# VPAC0_CTSET2_WRAP_CFG_CTSET2_CFG register map
Vendor: Texas Instruments
Peripheral module from a debugger description file (folder J7ES).
Registers are 32-bit, access per field, reset 0x0 unless marked. A register's access mark holds for its fields unless they carry their own. Offsets are as the file gives them; lines under a group give offsets from that group; [hi:lo] are bit positions; {n}, {i} and the like mark numbered series; 'fields as' and 'values as' point back to an identical list; <NAME> marks a mode.

## VPAC0_CTSET2_WRAP_CFG_CTSET2_CFG
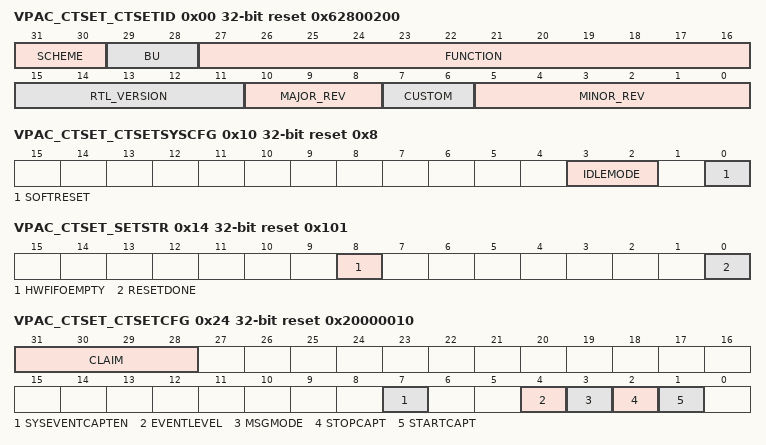
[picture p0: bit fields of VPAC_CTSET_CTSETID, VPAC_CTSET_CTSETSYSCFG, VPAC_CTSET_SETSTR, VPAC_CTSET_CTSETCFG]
0x00 VPAC_CTSET_CTSETID ro reset 0x62800200 — CTSET identification register
  [31:30] SCHEME — Used to distinguish between old Scheme and current
  [29:28] BU — The value 10b designates this as Processor Business Unit IP
  [27:16] FUNCTION — Function : Indicates a Debug IP (0x2nn) and 0x80 is the identifier for CT-SET
  [15:11] RTL_VERSION — This field changes on bug fix, and resets to '0' when either Minor Revision or Major Revision field changes
  [10:8] MAJOR_REV — Major Revision.
  [7:6] CUSTOM — Indicates a special version for a particular device.
  [5:0] MINOR_REV — Minor Revision.
0x10 VPAC_CTSET_CTSETSYSCFG reset 0x8 — CTSET system configuration register
  [3:2] IDLEMODE rw — Sets the Idle Mode for CTSET (
  [0] SOFTRESET rw — This will reset entire CTSET, except the registers and the CFG interface.
0x14 VPAC_CTSET_SETSTR ro reset 0x101 — CTSET status register
  [8] HWFIFOEMPTY — System Event Trace FIFO status, 1 is empty, 0 means captured data not yet exported
  [0] RESETDONE — Reset status, 0 means reset ongoing, 1 indicates completed
0x18 VPAC_CTSET_DBGTIMELOW ro — The 32 low order bits of the debug time value supplied on the time input interface
  [31:0] DBGTIME — debug time
0x1C VPAC_CTSET_DBGTIMEHI ro — The 32 high order bits of the debug time value supplied on the time input interface
  [31:0] DBGTIME — debug time
0x24 VPAC_CTSET_CTSETCFG reset 0x20000010 — The 32 low order bits of the debug time value supplied on the time input interface The 32 high order bits of the debug time value supplied on the time input interface. Reading latches the lower 32 bits of debug time value CTSET configuration register
  [31:28] CLAIM rw — Claim control and status.
  [7] SYSEVENTCAPTEN rw — When 1 the System event capture is enabled
  [4] EVENTLEVEL rw — 0 enables low level event detection, 1 enables high level event detection
  [3] MSGMODE rw — Message generated based on event detection, 0 is sampling window, 1 is event detection
  [2] STOPCAPT rw — Stop capturing system events from external trigger detection
  [1] STARTCAPT rw — Start capturing system events from external trigger detection
0x28 VPAC_CTSET_SETSPLREG — System Event Sampling Window register
  [7:0] WINDOWSIZE rw — System events sampling window size expressed as CTSET cycles
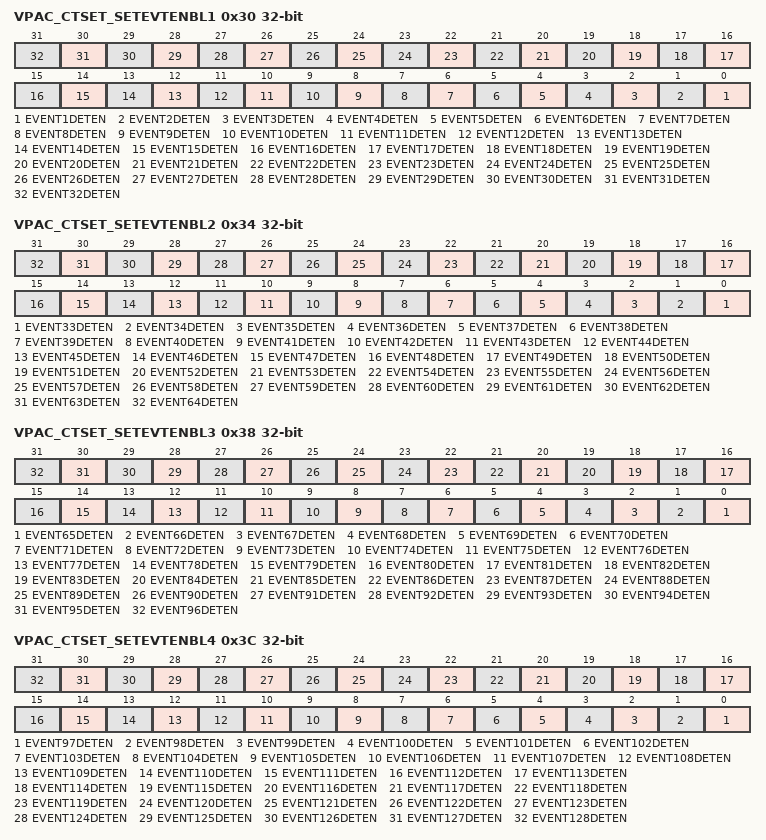
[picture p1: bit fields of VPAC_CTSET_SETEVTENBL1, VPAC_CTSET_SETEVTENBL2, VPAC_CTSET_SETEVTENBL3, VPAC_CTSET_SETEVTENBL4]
0x30 VPAC_CTSET_SETEVTENBL1 rw — System event detection enable register 1
  [n-1] EVENT{n}DETEN (n=1..32) — Event({n}) Detection Enable
0x34 VPAC_CTSET_SETEVTENBL2 rw — System event detection enable register 2 (if number of events > 32)
  [n-33] EVENT{n}DETEN (n=33..64) — Event({n}) Detection Enable
0x38 VPAC_CTSET_SETEVTENBL3 rw — System event detection enable register 3 (if number of events > 64)
  [n-65] EVENT{n}DETEN (n=65..96) — Event({n}) Detection Enable
0x3C VPAC_CTSET_SETEVTENBL4 rw — System event detection enable register 4 (if number of events > 96)
  [n-97] EVENT{n}DETEN (n=97..128) — Event({n}) Detection Enable
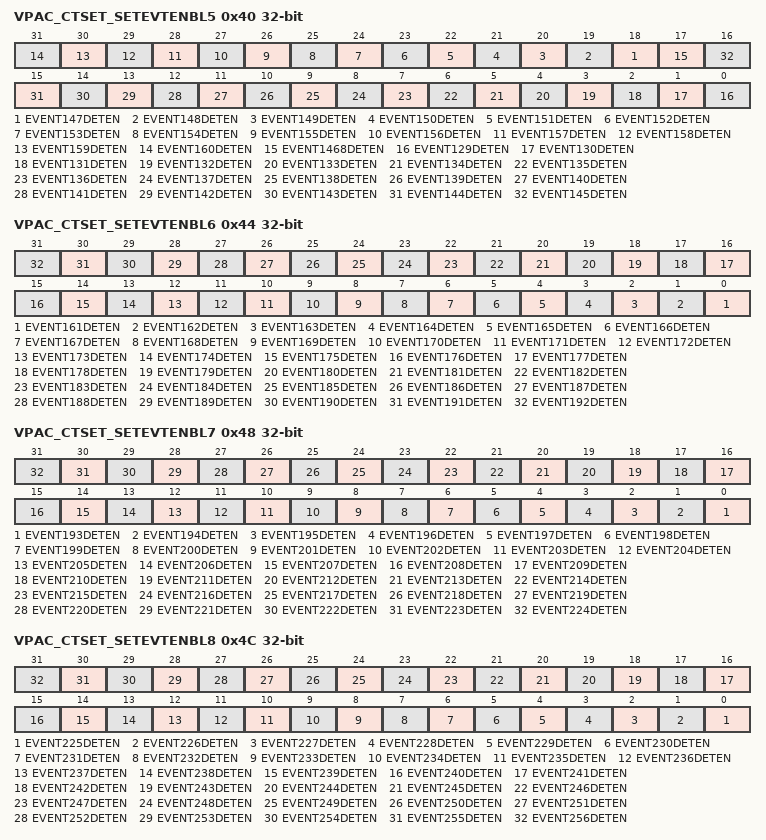
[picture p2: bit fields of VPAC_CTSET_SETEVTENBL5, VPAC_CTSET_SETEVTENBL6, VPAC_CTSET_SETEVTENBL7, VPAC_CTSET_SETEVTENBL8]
0x40 VPAC_CTSET_SETEVTENBL5 rw — System event detection enable register 5 (if number of events > 128)
  [n-129] EVENT{n}DETEN (n=147..160) — Event({n}) Detection Enable
  [17] EVENT1468DETEN — Event(146) Detection Enable
  [n-129] EVENT{n}DETEN (n=129..145) — Event({n}) Detection Enable
0x44 VPAC_CTSET_SETEVTENBL6 rw — System event detection enable register 6 (if number of events > 160)
  [n-161] EVENT{n}DETEN (n=161..192) — Event({n}) Detection Enable
0x48 VPAC_CTSET_SETEVTENBL7 rw — System event detection enable register 7 (if number of events > 192)
  [n-193] EVENT{n}DETEN (n=193..224) — Event({n}) Detection Enable
0x4C VPAC_CTSET_SETEVTENBL8 rw — System event detection enable register 8 (if number of events > 224)
  [n-225] EVENT{n}DETEN (n=225..256) — Event({n}) Detection Enable
0x50 VPAC_CTSET_SETMSTID — System Event Master ID
  [7:0] MASTID rw — HW Master ID for System Event module.
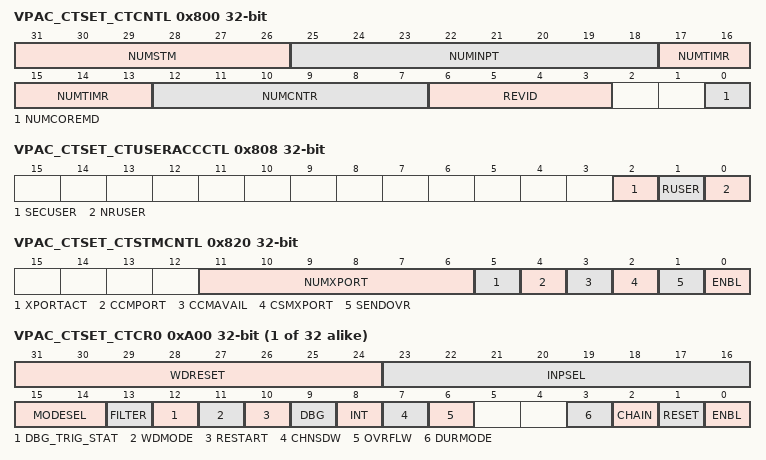
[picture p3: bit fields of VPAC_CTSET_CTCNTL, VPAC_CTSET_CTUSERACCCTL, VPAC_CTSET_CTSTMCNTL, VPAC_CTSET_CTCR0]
0x800 VPAC_CTSET_CTCNTL ro — Counter Timer Control
  [31:26] NUMSTM — Number of counters that can export via STM
  [25:18] NUMINPT — Number of event input signals
  [17:13] NUMTIMR — Number of timers in the module
  [12:7] NUMCNTR — Number of counters in the module
  [6:3] REVID — Revision ID of CTSET
  [0] NUMCOREMD — Indicated the number of mode bus interfaces, 0 is 2 CPU buses, 1 is 4 buses
0x804 VPAC_CTSET_CTNUMDBG ro — Counter Timer Number Debug Event Register
  [2:0] NUMEVT — Number of input selectors for debug events
0x808 VPAC_CTSET_CTUSERACCCTL — Counter Timer User Access Control, can only be written in priviledged mode
  [2] SECUSER rw — Counter functions while system is in Secure-User mode
  [1] RUSER rw — Counter functions while system is in Root-User mode
  [0] NRUSER rw — Counter functions while system is in in Non-Root-User mode
0x820 VPAC_CTSET_CTSTMCNTL — Counter Timer STM Control register
  [11:6] NUMXPORT ro — The total number of counters designated for export
  [5] XPORTACT ro — Indicates if a frame is currently being written to the STM.
  [4] CCMPORT rw — SW control of CCM message export
  [3] CCMAVAIL rw — CTSET supports CCM export
  [2] CSMXPORT rw — SW control of CSM message export
  [1] SENDOVR rw — Send overflow data in CSM frame
  [0] ENBL rw — CTSET STM global enable for counter/timer messages
0x824 VPAC_CTSET_CTSTMMSTID — Counter Timer STM Master ID register
  [7:0] MASTID rw — HW Master ID for System Event module
0x828 VPAC_CTSET_CTSTMINTVL — Counter Timer STM Interval Register
  [14:0] INTERVAL rw — Counter Timer Periodic export interval
0x82C VPAC_CTSET_CTSTMSEL0 rw — Counter Timer STM Counter Select Register 0. This Selects Counter 0 to 31
  [31:0] COUNTSEL — The individual bit is this field indicate whether the corresponding counter value is included in the CSM message generated via the STM interface
0x830 VPAC_CTSET_CTSTMSEL1 rw — Counter Timer STM Counter Select Register 1. This Selects Counter 32 to 63
  fields as VPAC_CTSET_CTSTMSEL0
{0x840+4i} VPAC_CTSET_CTINTVLR{i} rw (i=0..15) — These registers contain the interval match value for the corresponding timers in the CTSET. TINTVLRn are available based on number of timers instantiated.
  [31:0] INTERVAL — Interval match value for the timers in the CTSET
0x8A0 VPAC_CTSET_CTDBGSGL0 — Timer Interval Register 0. Interval match value for timer 0 in CTSET Timer Interval Register 1. Interval match value for timer 1 in CTSET Timer Interval Register 2. Interval match value for timer 2 in CTSET Timer Interval Register 3. Interval match value for timer 3 in CTSET Timer Interval Register 4. Interval match value for timer 4 in CTSET Timer Interval Register 5. Interval match value for timer 5 in CTSET Timer Interval Register 6. Interval match value for timer 6 in CTSET Timer Interval Register 7. Interval match value for timer 7 in CTSET Timer Interval Register 8. Interval match value for timer 8 in CTSET Timer Interval Register 9. Interval match value for timer 9 in CTSET Timer Interval Register 10. Interval match value for timer 10 in CTSET Timer Interval Register 11. Interval match value for timer 11 in CTSET Timer Interval Register 12. Interval match value for timer 12 in CTSET Timer Interval Register 13. Interval match value for timer 13 in CTSET Timer Interval Register 14. Interval match value for timer 14 in CTSET Timer Interval Register 15. Interval match value for timer 15 in CTSET Counter Timer Debug Event Register 0
  [7:0] INPSEL rw — Counter Timer input selection
{0x8A0+4i} VPAC_CTSET_CTDBGSGL{i} (i=1..4) — Counter Timer Debug Event Register {i}
  [7:0] INPSEL rw — Counter Timer input selection
0x8B4 VPAC_CTSET_CTDBGSGL5 — Counter Timer Debug Event Register5
  [7:0] INPSEL rw — Counter Timer input selection
0x8B8 VPAC_CTSET_CTDBGSGL6 — Counter Timer Debug Event Register 6
  [7:0] INPSEL rw — Counter Timer input selection
0x8BC VPAC_CTSET_CTDBGSGL7 — Counter Timer Debug Event Register 7
  [7:0] INPSEL rw — Counter Timer input selection
0x9F0 VPAC_CTSET_CTGNBL0 rw — Counter Timer Global Enable Register 0. This enables Counter 0 to 31
  [7:0] ENABLE — The individual bit is this field enables the corresponding counter.
0x9F4 VPAC_CTSET_CTGNBL1 rw — Counter Timer Global Enable Register 1. This enables Counter 32 to 63
  [7:0] ENABLE — The individual bit is this field enables the corresponding counter
0x9F8 VPAC_CTSET_CTGRST0 rw — Counter Timer Global Reset Register 0. This resets Counter 0 to 31
  [7:0] RESET — The individual bit is this field resets the corresponding counter.
0x9FC VPAC_CTSET_CTGRST1 rw — Counter Timer Global Reset Register 0. This resets Counter 32 to 63
  fields as VPAC_CTSET_CTGRST0
{0xA00+4i} VPAC_CTSET_CTCR{i} (i=0..31) — Counter Timer Control Register {i}
  [31:24] WDRESET rw — WD reset event input selector.
  [23:16] INPSEL rw — Counter Timer input selection.
  [15:14] MODESEL rw — Counter is in duration or occurrence mode.
  [13] FILTER rw — Use associated operating mode filter in CTMODEFILTERn
  [12] DBG_TRIG_STAT rw — Debug event triggered.
  [11] WDMODE rw — WD Timer mode selection.
  [10] RESTART rw — Restart the timer after an interval match.
  [9] DBG rw — Signal debug logic on interval match.
  [8] INT rw — Generate interrupt on interval match.
  [7] CHNSDW rw — Counter has a shadow register for chain reads.
  [6] OVRFLW rw — Counter is in duration or occurrence mode
  [3] DURMODE rw — Counter is in duration or occurrence mode
  [2] CHAIN rw — Counter is chained to an adjacent counter
  [1] RESET rw — Counter reset control
  [0] ENBL rw — Counter enable control
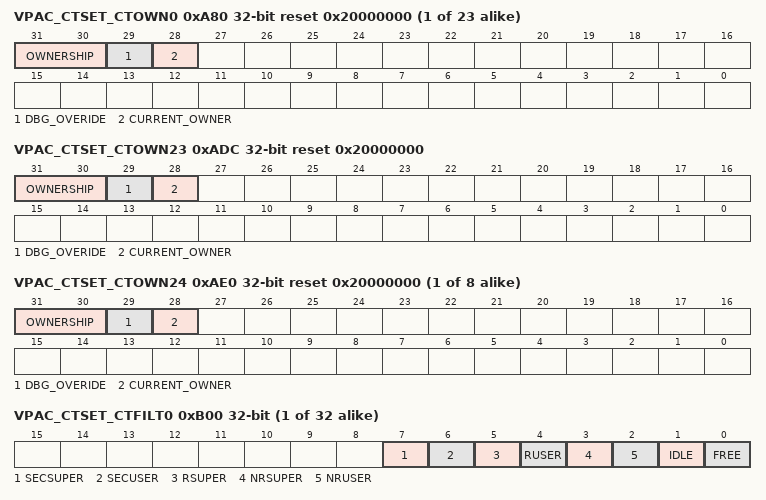
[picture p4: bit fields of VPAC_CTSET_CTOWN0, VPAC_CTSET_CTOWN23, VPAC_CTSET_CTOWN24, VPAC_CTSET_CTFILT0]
{0xA80+4i} VPAC_CTSET_CTOWN{i} reset 0x20000000 (i=0..22) — Counter/Timer Ownership register {i}
  [31:30] OWNERSHIP rw — Counter/Timer Ownership Status.
  [29] DBG_OVERIDE rw — This bit indicates the debugger is Claiming the resource, always reads back as 1
  [28] CURRENT_OWNER ro — This value reflects the Counter/Timer ownership when the register is in a non-Available state,
0xADC VPAC_CTSET_CTOWN23 reset 0x20000000 — Counter/Timer Ownership register2 3
  fields as VPAC_CTSET_CTOWN0
{0xA80+4i} VPAC_CTSET_CTOWN{i} reset 0x20000000 (i=24..31) — Counter/Timer Ownership register {i}
  fields as VPAC_CTSET_CTOWN0
{0xB00+4i} VPAC_CTSET_CTFILT{i} (i=0..31) — Counter Timer {i} Filter Register. These filters are only activated if the CTCRn : FILTER is set
  [7] SECSUPER rw — Counter functions while system is in Secure-Supervisor mode
  [6] SECUSER rw — Counter functions while system is in Secure-User mode
  [5] RSUPER rw — Counter functions while system is in Root-Supervisor node
  [4] RUSER rw — Counter functions while system is in Root-User mode
  [3] NRSUPER rw — Counter functions while system is in Non-Root-Supervisor mode
  [2] NRUSER rw — Counter functions while system is in in Non-Root-User mode
  [1] IDLE rw — Counter functions while system/core is in idle
  [0] FREE rw — Counter functions while system/core is halted
{0xB80+4i} VPAC_CTSET_CTCNTR{i} ro (i=0..31) — Counter Timer Counter Register {i}
  [31:0] COUNT — This field reflects the current value of the counter.
0xC00 VPAC_CTSET_CT_EOI — Counter Timer EOI Register. This register is the End of Interrupt used by SW to signal HW that an interrupt event service is complete and an interrupt can be rearmed. This register exists only if NUMTIMR > 0 The EOI register is used to re-trigger the pulse interrupt signal to ensure that any nested interrupt events are serviced. The software interrupt handler must write to the EOI register at the end of the current interrupt processing routine, so that new events can re-trigger the pulse interrupt signal again. For level interrupt signals the EOI register is not functional and must not be used.
  [0] EOI rw — EOI value
0xC04 VPAC_CTSET_CTIRQSTAT_RAW rw — Counter Timer IRQSTATUS RAW Register. This register indicates the raw status of the interrupt. It can be written by SW for testing. This register exists only if NUMTIMR > 0
  [31:0] TIM_INTN_IRQ — IRQSTATUS_RAW value.
0xC08 VPAC_CTSET_CTIRQSTAT rw — Counter Timer IRQSTATUS Register. This bit clears the interrupt event. SW can also read this bit to indicate that the interrupt is active and enabled. This register exists only if NUMTIMR > 0
  [31:0] TIM_INTN_IE — IRQSTATUS value.
0xC0C VPAC_CTSET_CTIRQENABLE_SET rw — Counter Timer IRQENABLE_SET Register. This register is to enable generation of Interrupt Event used by SW. This register exists only if NUMTIMR > 0
  [31:0] TIM_INTN_IES — IRQSET value.
0xC10 VPAC_CTSET_CTIRQENABLE_CLR rw — Counter Timer IRQENABLE_CLR Register. This register is to disable generation of Interrupt Event used by SW. This register exists only if NUMTIMR > 0
  [31:0] TIM_INTN_IEC — IRQCLR value.
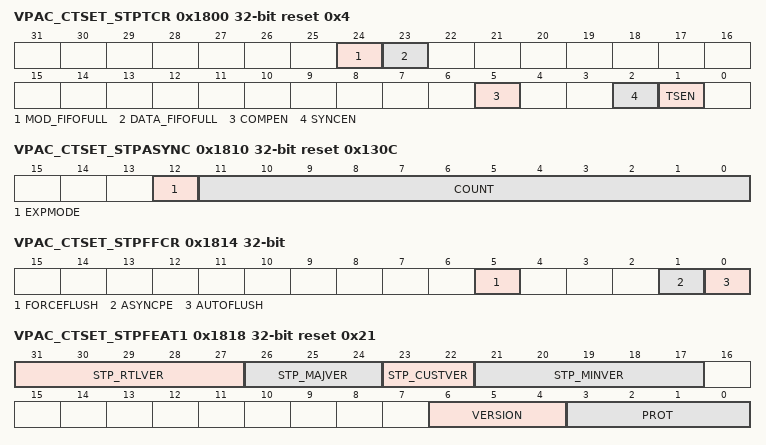
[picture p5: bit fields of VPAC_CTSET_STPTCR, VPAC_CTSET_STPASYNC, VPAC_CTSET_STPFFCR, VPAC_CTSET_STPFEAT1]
0x1800 VPAC_CTSET_STPTCR reset 0x4 — STP Trace Control Register
  [24] MOD_FIFOFULL ro — STPMI2ATB internal MID packet fifo is full
  [23] DATA_FIFOFULL ro — STPMI2ATB internal Data packet fifo is full
  [5] COMPEN rw — Compression of Data enable
  [2] SYNCEN ro — The value 1 indicates
  [1] TSEN rw — Timestamp Enable.
0x1804 VPAC_CTSET_STPTID — STP Trace ID Register
  [6:0] TRACEID rw — Trace ID value.
0x1810 VPAC_CTSET_STPASYNC reset 0x130C — STP Synchronization Control Register
  [12] EXPMODE rw — Exponent mode, A value of 1 sets count to 2 to the Nth, where Nth is ((bits
  [11:0] COUNT rw — The number of bytes between Synchronization packets
0x1814 VPAC_CTSET_STPFFCR — STP Flush Control Register
  [5] FORCEFLUSH rw — Write a 1 to force a flush, automatically clears after the operation is complete
  [1] ASYNCPE rw — Async Priority Enable.
  [0] AUTOFLUSH rw — Auto flush enable.
0x1818 VPAC_CTSET_STPFEAT1 ro reset 0x21 — STP Features 1 Register
  [31:27] STP_RTLVER — RTL Version.
  [26:24] STP_MAJVER — Functional Major Version.
  [23:22] STP_CUSTVER — Custom Version (not used)
  [21:17] STP_MINVER — Functional Minor Version
  [6:4] VERSION — STP2.0 Time Stamp, Value of 011 indicates Natural binary timestamp, a value of 100 indicates gray binary timestamps
  [3:0] PROT — Protocol Revision.
